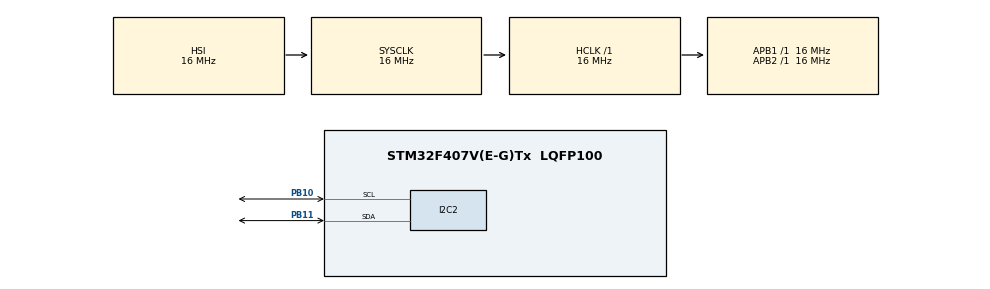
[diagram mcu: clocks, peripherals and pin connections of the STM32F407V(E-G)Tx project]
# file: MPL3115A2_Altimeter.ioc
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Mcu.Family=STM32F4
Mcu.Name=STM32F407V(E-G)Tx
Mcu.Package=LQFP100
NVIC.PriorityGroup=NVIC_PRIORITYGROUP_4
PB10.Mode=I2C
PB10.Signal=I2C2_SCL
PB11.Mode=I2C
PB11.Signal=I2C2_SDA
ProjectManager.HeapSize=0x200
ProjectManager.StackSize=0x400
ProjectManager.TargetToolchain=STM32CubeIDE
RCC.AHBFreq_Value=16000000
RCC.APB1Freq_Value=16000000
RCC.APB2Freq_Value=16000000
RCC.CortexFreq_Value=16000000
RCC.HSE_VALUE=25000000
RCC.HSI_VALUE=16000000
RCC.LSE_VALUE=32768
RCC.SYSCLKFreq_VALUE=16000000
RCC.VCOOutputFreq_Value=192000000
board=custom

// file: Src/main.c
/* USER CODE BEGIN Header */
/**
  ******************************************************************************
  * @file           : main.c
  * @brief          : Main program body
  ******************************************************************************
  * @attention
  *
  * <h2><center>&copy; Copyright (c) 2021 STMicroelectronics.
  * All rights reserved.</center></h2>
  *
  * This software component is licensed by ST under BSD 3-Clause license,
  * the "License"; You may not use this file except in compliance with the
  * License. You may obtain a copy of the License at:
  *                        opensource.org/licenses/BSD-3-Clause
  *
  ******************************************************************************
  */
/* USER CODE END Header */

#include "main.h"

/* USER CODE BEGIN Includes */
#include "stdbool.h"
#include "MPL3115A2.h"
/* USER CODE END Includes */

/* USER CODE BEGIN PD */
bool MPL_Start=false;
bool MplError=false;
bool MplInitialize=false;

float pressure=0.0;
float alt=0.0;
float temperature=0.0;

int32_t timeoutSecond=0;
int32_t timeoutmiliSecond=0;

/* USER CODE END PD */

I2C_HandleTypeDef hi2c2;

void SystemClock_Config(void);
static void MX_GPIO_Init(void);
static void MX_I2C2_Init(void);

int main(void)
{

  /* MCU Configuration--------------------------------------------------------*/

  /* Reset of all peripherals, Initializes the Flash interface and the Systick. */
  HAL_Init();

  /* Configure the system clock */
  SystemClock_Config();

  /* Initialize all configured peripherals */
  MX_GPIO_Init();
  MX_I2C2_Init();

  /* Infinite loop */
  while (1)
  {

    /* USER CODE BEGIN 3 */

	  if(Mpl3115A2_Begin())

	  {

        alt=MPL3115A2_ReadAltitude();
        HAL_Delay(100);
   		pressure= ((float)MPL3115A2_ReadPressure())/(float)3377.0f;
   	    HAL_Delay(10);

		temperature=MPL3115A2_ReadTemperature();

      }

  }
  /* USER CODE END 3 */
}

void SystemClock_Config(void)
{
  RCC_OscInitTypeDef RCC_OscInitStruct = {0};
  RCC_ClkInitTypeDef RCC_ClkInitStruct = {0};

  /** Configure the main internal regulator output voltage
  */
  __HAL_RCC_PWR_CLK_ENABLE();
  __HAL_PWR_VOLTAGESCALING_CONFIG(PWR_REGULATOR_VOLTAGE_SCALE1);
  /** Initializes the CPU, AHB and APB busses clocks
  */
  RCC_OscInitStruct.OscillatorType = RCC_OSCILLATORTYPE_HSI;
  RCC_OscInitStruct.HSIState = RCC_HSI_ON;
  RCC_OscInitStruct.HSICalibrationValue = RCC_HSICALIBRATION_DEFAULT;
  RCC_OscInitStruct.PLL.PLLState = RCC_PLL_NONE;
  if (HAL_RCC_OscConfig(&RCC_OscInitStruct) != HAL_OK)
  {
    Error_Handler();
  }
  /** Initializes the CPU, AHB and APB busses clocks
  */
  RCC_ClkInitStruct.ClockType = RCC_CLOCKTYPE_HCLK|RCC_CLOCKTYPE_SYSCLK
                              |RCC_CLOCKTYPE_PCLK1|RCC_CLOCKTYPE_PCLK2;
  RCC_ClkInitStruct.SYSCLKSource = RCC_SYSCLKSOURCE_HSI;
  RCC_ClkInitStruct.AHBCLKDivider = RCC_SYSCLK_DIV1;
  RCC_ClkInitStruct.APB1CLKDivider = RCC_HCLK_DIV1;
  RCC_ClkInitStruct.APB2CLKDivider = RCC_HCLK_DIV1;

  if (HAL_RCC_ClockConfig(&RCC_ClkInitStruct, FLASH_LATENCY_0) != HAL_OK)
  {
    Error_Handler();
  }
}

static void MX_I2C2_Init(void)
{

  hi2c2.Instance = I2C2;
  hi2c2.Init.ClockSpeed = 100000;
  hi2c2.Init.DutyCycle = I2C_DUTYCYCLE_2;
  hi2c2.Init.OwnAddress1 = 0;
  hi2c2.Init.AddressingMode = I2C_ADDRESSINGMODE_7BIT;
  hi2c2.Init.DualAddressMode = I2C_DUALADDRESS_DISABLE;
  hi2c2.Init.OwnAddress2 = 0;
  hi2c2.Init.GeneralCallMode = I2C_GENERALCALL_DISABLE;
  hi2c2.Init.NoStretchMode = I2C_NOSTRETCH_DISABLE;
  if (HAL_I2C_Init(&hi2c2) != HAL_OK)
  {
    Error_Handler();
  }

}

static void MX_GPIO_Init(void)
{

  /* GPIO Ports Clock Enable */
  __HAL_RCC_GPIOB_CLK_ENABLE();

}

void Error_Handler(void)
{
}

/************************ (C) COPYRIGHT STMicroelectronics *****END OF FILE****/
